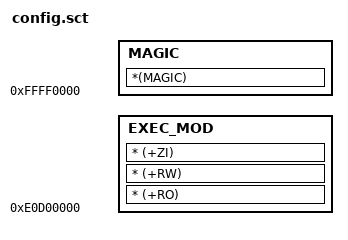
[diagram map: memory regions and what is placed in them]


;#include "syssct.sct"

LO_FIRST 0xe0d00000 0x8000
{
    EXEC_MOD  0xe0d00000                           ;// 内核代码和数据区,其中30是用于存放KRNL_HEAD代码
    {
        * (+RO)
        * (+RW)
        * (+ZI)
    }
    MAGIC  0xFFFF0000
    {
        *(MAGIC)
    }
}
